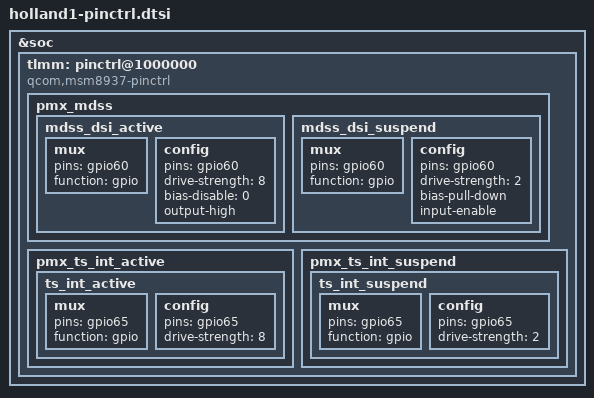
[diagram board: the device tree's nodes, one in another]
/*
 * Copyright (c) 2015-2016, The Linux Foundation. All rights reserved.
 *
 * Copyright (c) 2020, Shubham-Panwar.
 *
 * This program is free software; you can redistribute it and/or modify
 * it under the terms of the GNU General Public License version 2 and
 * only version 2 as published by the Free Software Foundation.
 *
 * This program is distributed in the hope that it will be useful,
 * but WITHOUT ANY WARRANTY; without even the implied warranty of
 * MERCHANTABILITY or FITNESS FOR A PARTICULAR PURPOSE.  See the
 * GNU General Public License for more details.
 */

&soc {
	tlmm: pinctrl@1000000 {
		compatible = "qcom,msm8937-pinctrl";

        pmx_mdss: pmx_mdss {
			mdss_dsi_active: mdss_dsi_active {
				mux {
					pins = "gpio60"; /*"gpio98", "gpio99";  wenchao add*/
					function = "gpio";
				};
                
                config {
					pins = "gpio60";/* "gpio98", "gpio99";*/
					drive-strength = <8>; /* 8 mA */
					bias-disable = <0>; /* no pull */
					output-high;
				};
			};
            
            mdss_dsi_suspend: mdss_dsi_suspend {
				mux {
					pins = "gpio60";/* "gpio98", "gpio99";*/
					function = "gpio";
				};

				config {
					pins = "gpio60";/* "gpio98", "gpio99";*/
					drive-strength = <2>; /* 2 mA */
					bias-pull-down; /* pull down */
					input-enable;
				};
			};
		};
        
            /* add pingrp for touchscreen */
		pmx_ts_int_active {
			ts_int_active: ts_int_active {
				mux {
					pins = "gpio65";
					function = "gpio";
				};

				config {
					pins = "gpio65";
					drive-strength = <8>;
				};
			};
		};

		pmx_ts_int_suspend {
			ts_int_suspend: ts_int_suspend {
				mux {
					pins = "gpio65";
					function = "gpio";
				};

				config {
					pins = "gpio65";
					drive-strength = <2>;
				};
			};
		};
    };
};
